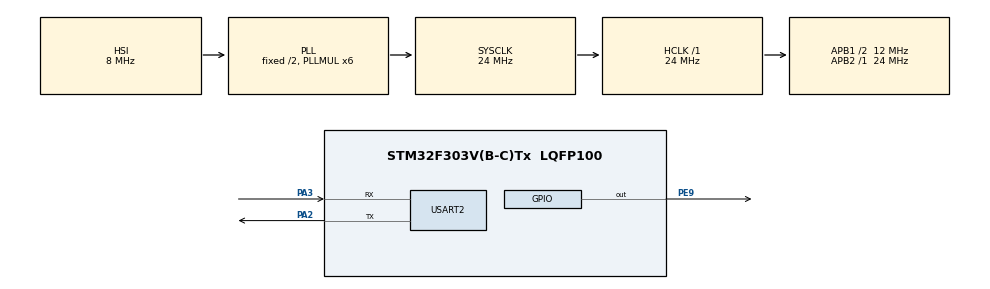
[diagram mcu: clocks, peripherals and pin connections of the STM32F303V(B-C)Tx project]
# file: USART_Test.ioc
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Mcu.Family=STM32F3
Mcu.Name=STM32F303V(B-C)Tx
Mcu.Package=LQFP100
NVIC.PriorityGroup=NVIC_PRIORITYGROUP_0
NVIC.TIM2_IRQn=true\:0\:0\:false\:false\:true\:true
PA13.Mode=Serial_Wire
PA13.Signal=SYS_JTMS-SWDIO
PA14.Mode=Serial_Wire
PA14.Signal=SYS_JTCK-SWCLK
PA2.Mode=Asynchronous
PA2.Signal=USART2_TX
PA3.Mode=Asynchronous
PA3.Signal=USART2_RX
PE9.Signal=GPIO_Output
ProjectManager.HeapSize=0x200
ProjectManager.StackSize=0x400
ProjectManager.TargetToolchain=MDK-ARM V5
RCC.AHBFreq_Value=24000000
RCC.APB1CLKDivider=RCC_HCLK_DIV2
RCC.APB1Freq_Value=12000000
RCC.APB1TimFreq_Value=24000000
RCC.APB2Freq_Value=24000000
RCC.APB2TimFreq_Value=24000000
RCC.CortexFreq_Value=24000000
RCC.HCLKFreq_Value=24000000
RCC.HSE_VALUE=8000000
RCC.HSI_VALUE=8000000
RCC.LSE_VALUE=32768
RCC.PLLMUL=RCC_PLL_MUL6
RCC.SYSCLKFreq_VALUE=24000000
RCC.SYSCLKSourceVirtual=RCC_SYSCLKSOURCE_PLLCLK
RCC.USBFreq_Value=24000000
TIM2.Period=1000
TIM2.Prescaler=16000
USART2.VirtualMode-Asynchronous=VM_ASYNC
VP_TIM2_VS_ClockSourceINT.Mode=Internal
board=STM32F3DISCOVERY

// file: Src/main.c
/**
  ******************************************************************************
  * @file           : main.c
  * @brief          : Main program body
  ******************************************************************************
  ** This notice applies to any and all portions of this file
  * that are not between comment pairs USER CODE BEGIN and
  * USER CODE END. Other portions of this file, whether
  * inserted by the user or by software development tools
  * are owned by their respective copyright owners.
  *
  * COPYRIGHT(c) 2018 STMicroelectronics
  *
  * Redistribution and use in source and binary forms, with or without modification,
  * are permitted provided that the following conditions are met:
  *   1. Redistributions of source code must retain the above copyright notice,
  *      this list of conditions and the following disclaimer.
  *   2. Redistributions in binary form must reproduce the above copyright notice,
  *      this list of conditions and the following disclaimer in the documentation
  *      and/or other materials provided with the distribution.
  *   3. Neither the name of STMicroelectronics nor the names of its contributors
  *      may be used to endorse or promote products derived from this software
  *      without specific prior written permission.
  *
  * THIS SOFTWARE IS PROVIDED BY THE COPYRIGHT HOLDERS AND CONTRIBUTORS "AS IS"
  * AND ANY EXPRESS OR IMPLIED WARRANTIES, INCLUDING, BUT NOT LIMITED TO, THE
  * IMPLIED WARRANTIES OF MERCHANTABILITY AND FITNESS FOR A PARTICULAR PURPOSE ARE
  * DISCLAIMED. IN NO EVENT SHALL THE COPYRIGHT HOLDER OR CONTRIBUTORS BE LIABLE
  * FOR ANY DIRECT, INDIRECT, INCIDENTAL, SPECIAL, EXEMPLARY, OR CONSEQUENTIAL
  * DAMAGES (INCLUDING, BUT NOT LIMITED TO, PROCUREMENT OF SUBSTITUTE GOODS OR
  * SERVICES; LOSS OF USE, DATA, OR PROFITS; OR BUSINESS INTERRUPTION) HOWEVER
  * CAUSED AND ON ANY THEORY OF LIABILITY, WHETHER IN CONTRACT, STRICT LIABILITY,
  * OR TORT (INCLUDING NEGLIGENCE OR OTHERWISE) ARISING IN ANY WAY OUT OF THE USE
  * OF THIS SOFTWARE, EVEN IF ADVISED OF THE POSSIBILITY OF SUCH DAMAGE.
  *
  ******************************************************************************
  */
#include "main.h"
#include "stm32f3xx_hal.h"

TIM_HandleTypeDef htim2;

UART_HandleTypeDef huart2;

/* USER CODE BEGIN PV */
/* Private variables ---------------------------------------------------------*/

/* USER CODE END PV */

void SystemClock_Config(void);
static void MX_GPIO_Init(void);
static void MX_TIM2_Init(void);
static void MX_USART2_UART_Init(void);

/* USER CODE BEGIN PFP */
/* Private function prototypes -----------------------------------------------*/

/* USER CODE END PFP */

/* USER CODE BEGIN 0 */
#include "stdio.h"
#include "string.h"
char aTxBuffer[1024];
/* USER CODE END 0 */

int main(void)
{

  /* MCU Configuration----------------------------------------------------------*/

  /* Reset of all peripherals, Initializes the Flash interface and the Systick. */
  HAL_Init();

  /* Configure the system clock */
  SystemClock_Config();

  /* Initialize all configured peripherals */
  MX_GPIO_Init();
  MX_TIM2_Init();
  MX_USART2_UART_Init();
  /* USER CODE BEGIN 2 */
	HAL_TIM_Base_Start_IT(&htim2);

  /* USER CODE END 2 */

  /* Infinite loop */
  /* USER CODE BEGIN WHILE */

	const uint8_t str[] = "Hello World, from Olin!\n";
	uint8_t* strptr = (uint8_t*) str;

  while (1)
  {
		HAL_Delay(800);
		HAL_GPIO_TogglePin(GPIOE, GPIO_PIN_9);
		//HAL_UART_Transmit(&huart2, strptr, strlen(strptr), 0xFFFF);
		//sprintf(aTxBuffer, "Testing Uart \r\n");
		//HAL_UART_Transmit(&huart2, (uint8_t *)aTxBuffer, strlen(aTxBuffer), 5000);

  /* USER CODE END WHILE */

  }

}

void SystemClock_Config(void)
{

  RCC_OscInitTypeDef RCC_OscInitStruct;
  RCC_ClkInitTypeDef RCC_ClkInitStruct;
  RCC_PeriphCLKInitTypeDef PeriphClkInit;

    /**Initializes the CPU, AHB and APB busses clocks
    */
  RCC_OscInitStruct.OscillatorType = RCC_OSCILLATORTYPE_HSI;
  RCC_OscInitStruct.HSIState = RCC_HSI_ON;
  RCC_OscInitStruct.HSICalibrationValue = 16;
  RCC_OscInitStruct.PLL.PLLState = RCC_PLL_ON;
  RCC_OscInitStruct.PLL.PLLSource = RCC_PLLSOURCE_HSI;
  RCC_OscInitStruct.PLL.PLLMUL = RCC_PLL_MUL6;
  if (HAL_RCC_OscConfig(&RCC_OscInitStruct) != HAL_OK)
  {
    _Error_Handler(__FILE__, __LINE__);
  }

    /**Initializes the CPU, AHB and APB busses clocks
    */
  RCC_ClkInitStruct.ClockType = RCC_CLOCKTYPE_HCLK|RCC_CLOCKTYPE_SYSCLK
                              |RCC_CLOCKTYPE_PCLK1|RCC_CLOCKTYPE_PCLK2;
  RCC_ClkInitStruct.SYSCLKSource = RCC_SYSCLKSOURCE_PLLCLK;
  RCC_ClkInitStruct.AHBCLKDivider = RCC_SYSCLK_DIV1;
  RCC_ClkInitStruct.APB1CLKDivider = RCC_HCLK_DIV2;
  RCC_ClkInitStruct.APB2CLKDivider = RCC_HCLK_DIV1;

  if (HAL_RCC_ClockConfig(&RCC_ClkInitStruct, FLASH_LATENCY_0) != HAL_OK)
  {
    _Error_Handler(__FILE__, __LINE__);
  }

  PeriphClkInit.PeriphClockSelection = RCC_PERIPHCLK_USART2;
  PeriphClkInit.Usart2ClockSelection = RCC_USART2CLKSOURCE_PCLK1;
  if (HAL_RCCEx_PeriphCLKConfig(&PeriphClkInit) != HAL_OK)
  {
    _Error_Handler(__FILE__, __LINE__);
  }

    /**Configure the Systick interrupt time
    */
  HAL_SYSTICK_Config(HAL_RCC_GetHCLKFreq()/1000);

    /**Configure the Systick
    */
  HAL_SYSTICK_CLKSourceConfig(SYSTICK_CLKSOURCE_HCLK);

  /* SysTick_IRQn interrupt configuration */
  HAL_NVIC_SetPriority(SysTick_IRQn, 0, 0);
}

/* TIM2 init function */
static void MX_TIM2_Init(void)
{

  TIM_ClockConfigTypeDef sClockSourceConfig;
  TIM_MasterConfigTypeDef sMasterConfig;

  htim2.Instance = TIM2;
  htim2.Init.Prescaler = 16000;
  htim2.Init.CounterMode = TIM_COUNTERMODE_UP;
  htim2.Init.Period = 1000;
  htim2.Init.ClockDivision = TIM_CLOCKDIVISION_DIV1;
  htim2.Init.AutoReloadPreload = TIM_AUTORELOAD_PRELOAD_DISABLE;
  if (HAL_TIM_Base_Init(&htim2) != HAL_OK)
  {
    _Error_Handler(__FILE__, __LINE__);
  }

  sClockSourceConfig.ClockSource = TIM_CLOCKSOURCE_INTERNAL;
  if (HAL_TIM_ConfigClockSource(&htim2, &sClockSourceConfig) != HAL_OK)
  {
    _Error_Handler(__FILE__, __LINE__);
  }

  sMasterConfig.MasterOutputTrigger = TIM_TRGO_RESET;
  sMasterConfig.MasterSlaveMode = TIM_MASTERSLAVEMODE_DISABLE;
  if (HAL_TIMEx_MasterConfigSynchronization(&htim2, &sMasterConfig) != HAL_OK)
  {
    _Error_Handler(__FILE__, __LINE__);
  }

}

/* USART2 init function */
static void MX_USART2_UART_Init(void)
{

  huart2.Instance = USART2;
  huart2.Init.BaudRate = 38400;
  huart2.Init.WordLength = UART_WORDLENGTH_8B;
  huart2.Init.StopBits = UART_STOPBITS_1;
  huart2.Init.Parity = UART_PARITY_NONE;
  huart2.Init.Mode = UART_MODE_TX_RX;
  huart2.Init.HwFlowCtl = UART_HWCONTROL_NONE;
  huart2.Init.OverSampling = UART_OVERSAMPLING_16;
  huart2.Init.OneBitSampling = UART_ONE_BIT_SAMPLE_DISABLE;
  huart2.AdvancedInit.AdvFeatureInit = UART_ADVFEATURE_NO_INIT;
  if (HAL_UART_Init(&huart2) != HAL_OK)
  {
    _Error_Handler(__FILE__, __LINE__);
  }

}

/** Configure pins as
        * Analog
        * Input
        * Output
        * EVENT_OUT
        * EXTI
*/
static void MX_GPIO_Init(void)
{

  GPIO_InitTypeDef GPIO_InitStruct;

  /* GPIO Ports Clock Enable */
  __HAL_RCC_GPIOA_CLK_ENABLE();
  __HAL_RCC_GPIOE_CLK_ENABLE();

  /*Configure GPIO pin Output Level */
  HAL_GPIO_WritePin(GPIOE, GPIO_PIN_9, GPIO_PIN_RESET);

  /*Configure GPIO pin : PE9 */
  GPIO_InitStruct.Pin = GPIO_PIN_9;
  GPIO_InitStruct.Mode = GPIO_MODE_OUTPUT_PP;
  GPIO_InitStruct.Pull = GPIO_NOPULL;
  GPIO_InitStruct.Speed = GPIO_SPEED_FREQ_LOW;
  HAL_GPIO_Init(GPIOE, &GPIO_InitStruct);

}

/* USER CODE BEGIN 4 */
int nbtime=1;
void HAL_TIM_PeriodElapsedCallback(TIM_HandleTypeDef *htim){
	sprintf(aTxBuffer, "Testing Uart %d times\r\n", ++nbtime);
	HAL_UART_Transmit(&huart2, (uint8_t *)aTxBuffer, strlen(aTxBuffer), 5000);
}
/* USER CODE END 4 */

void _Error_Handler(char *file, int line)
{
  while(1)
  {
  }
}

/************************ (C) COPYRIGHT STMicroelectronics *****END OF FILE****/
